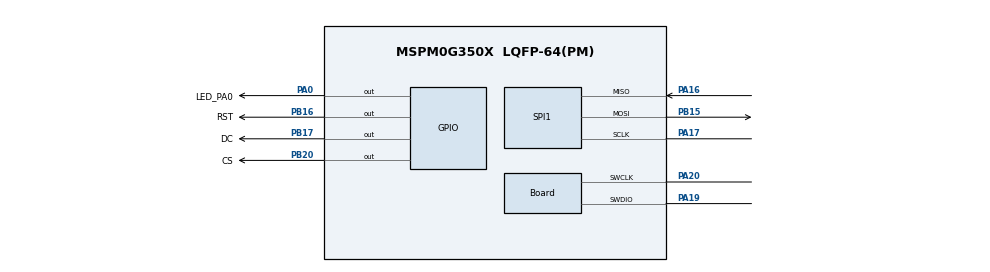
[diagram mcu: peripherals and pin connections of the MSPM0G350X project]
/**
 * @cliArgs --device "MSPM0G350X" --package "LQFP-64(PM)" --part "Default" --product "mspm0_sdk@2.00.01.00"
 * @versions {"tool":"1.20.0+3587"}
 */

/**
 * Import the modules used in this configuration.
 */
const GPIO          = scripting.addModule("/ti/driverlib/GPIO", {}, false);
const GPIO1         = GPIO.addInstance();
const GPIO2         = GPIO.addInstance();
const SPI           = scripting.addModule("/ti/driverlib/SPI", {}, false);
const SPI1          = SPI.addInstance();
const SYSCTL        = scripting.addModule("/ti/driverlib/SYSCTL");
const SYSTICK       = scripting.addModule("/ti/driverlib/SYSTICK");
const TIMER         = scripting.addModule("/ti/driverlib/TIMER", {}, false);
const TIMER1        = TIMER.addInstance();
const ProjectConfig = scripting.addModule("/ti/project_config/ProjectConfig");

/**
 * Write custom configuration values to the imported modules.
 */
const divider6       = system.clockTree["PLL_CLK2X_DIV"];
divider6.divideValue = 4;

const divider7       = system.clockTree["PLL_PDIV"];
divider7.divideValue = 2;

const multiplier2         = system.clockTree["PLL_QDIV"];
multiplier2.multiplyValue = 4;

const mux4       = system.clockTree["EXHFMUX"];
mux4.inputSelect = "EXHFMUX_XTAL";

const pinFunction4        = system.clockTree["HFXT"];
pinFunction4.enable       = true;
pinFunction4.inputFreq    = 40;
pinFunction4.HFXTStartup  = 20;
pinFunction4.HFCLKMonitor = true;

GPIO1.port                          = "PORTA";
GPIO1.$name                         = "USER_GPIO";
GPIO1.associatedPins[0].$name       = "LED_PA0";
GPIO1.associatedPins[0].pin.$assign = "PA0";

const Board                       = scripting.addModule("/ti/driverlib/Board", {}, false);
Board.peripheral.$assign          = "DEBUGSS";
Board.peripheral.swclkPin.$assign = "PA20";
Board.peripheral.swdioPin.$assign = "PA19";

GPIO2.$name                         = "PORTB";
GPIO2.associatedPins.create(3);
GPIO2.associatedPins[0].$name       = "RST";
GPIO2.associatedPins[0].pin.$assign = "PB16";
GPIO2.associatedPins[1].$name       = "DC";
GPIO2.associatedPins[1].pin.$assign = "PB17";
GPIO2.associatedPins[2].$name       = "CS";
GPIO2.associatedPins[2].pin.$assign = "PB20";

SPI1.$name                      = "SPI_0";
SPI1.frameFormat                = "MOTO3";
SPI1.polarity                   = "1";
SPI1.phase                      = "1";
SPI1.spiClkDiv                  = "2";
SPI1.targetBitRate              = 4000000;
SPI1.peripheral.$assign         = "SPI1";
SPI1.peripheral.sclkPin.$assign = "PA17";
SPI1.peripheral.mosiPin.$assign = "PB15";
SPI1.peripheral.misoPin.$assign = "PA16";
SPI1.sclkPinConfig.$name        = "ti_driverlib_gpio_GPIOPinGeneric2";
SPI1.mosiPinConfig.$name        = "ti_driverlib_gpio_GPIOPinGeneric3";
SPI1.misoPinConfig.$name        = "ti_driverlib_gpio_GPIOPinGeneric4";

SYSCTL.clockTreeEn = true;

SYSTICK.periodEnable    = true;
SYSTICK.systickEnable   = true;
SYSTICK.interruptEnable = true;
SYSTICK.period          = 32000;

TIMER1.$name              = "TIMER_1";
TIMER1.timerClkPrescale   = 256;
TIMER1.interrupts         = ["ZERO"];
TIMER1.timerMode          = "PERIODIC_UP";
TIMER1.timerPeriod        = "100 ms";
TIMER1.peripheral.$assign = "TIMA0";

ProjectConfig.deviceSpin = "MSPM0G3507";

/**
 * Pinmux solution for unlocked pins/peripherals. This ensures that minor changes to the automatic solver in a future
 * version of the tool will not impact the pinmux you originally saw.  These lines can be completely deleted in order to
 * re-solve from scratch.
 */
pinFunction4.peripheral.$suggestSolution           = "SYSCTL";
pinFunction4.peripheral.hfxInPin.$suggestSolution  = "PA5";
pinFunction4.peripheral.hfxOutPin.$suggestSolution = "PA6";
